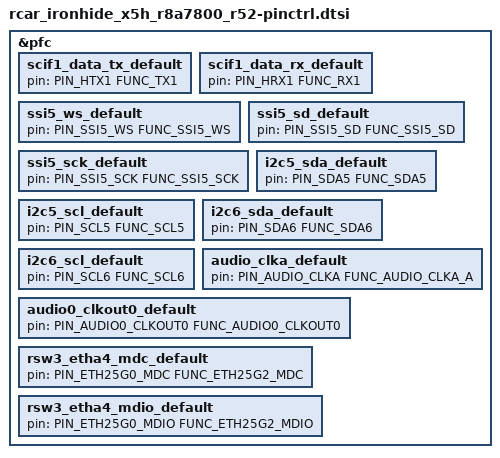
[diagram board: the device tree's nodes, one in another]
/*
 * Copyright (c) 2026 Renesas Electronics Corporation
 *
 * SPDX-License-Identifier: Apache-2.0
 */

#include <zephyr/dt-bindings/pinctrl/renesas/pinctrl-r8a7800.h>

&pfc {
	scif1_data_tx_default: scif1_data_tx_default {
		pin = <PIN_HTX1 FUNC_TX1>;
	};

	scif1_data_rx_default: scif1_data_rx_default {
		pin = <PIN_HRX1 FUNC_RX1>;
	};

	ssi5_ws_default: ssi5_ws_default {
		pin = <PIN_SSI5_WS FUNC_SSI5_WS>;
	};

	ssi5_sd_default: ssi5_sd_default {
		pin = <PIN_SSI5_SD FUNC_SSI5_SD>;
	};

	ssi5_sck_default: ssi5_sck_default {
		pin = <PIN_SSI5_SCK FUNC_SSI5_SCK>;
	};

	/* I2C */
	i2c5_sda_default: i2c5_sda_default {
		pin = <PIN_SDA5 FUNC_SDA5>;
	};

	i2c5_scl_default: i2c5_scl_default {
		pin = <PIN_SCL5 FUNC_SCL5>;
	};

	i2c6_sda_default: i2c6_sda_default {
		pin = <PIN_SDA6 FUNC_SDA6>;
	};

	i2c6_scl_default: i2c6_scl_default {
		pin = <PIN_SCL6 FUNC_SCL6>;
	};

	audio_clka_default: audio_clka_default {
		pin = <PIN_AUDIO_CLKA FUNC_AUDIO_CLKA_A>;
	};

	audio0_clkout0_default: audio0_clkout0_default {
		pin = <PIN_AUDIO0_CLKOUT0 FUNC_AUDIO0_CLKOUT0>;
	};

	rsw3_etha4_mdc_default: rsw3_etha4_mdc_default {
		pin = <PIN_ETH25G0_MDC FUNC_ETH25G2_MDC>;
	};

	rsw3_etha4_mdio_default: rsw3_etha4_mdio_default {
		pin = <PIN_ETH25G0_MDIO FUNC_ETH25G2_MDIO>;
	};
};
